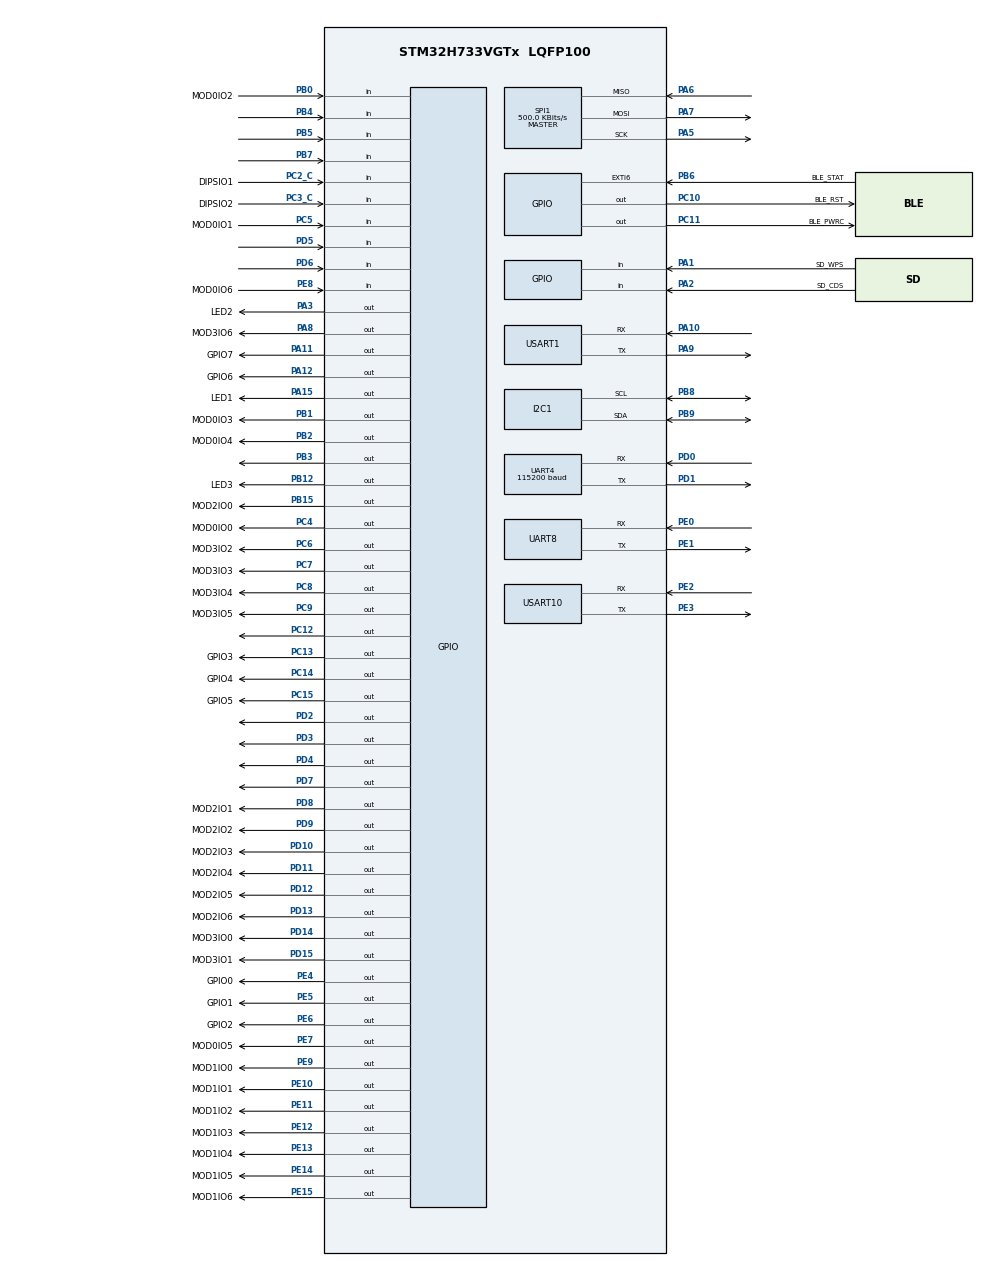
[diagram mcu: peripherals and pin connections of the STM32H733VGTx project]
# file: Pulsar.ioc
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Dma.Request0=UART4_RX
Dma.UART4_RX.0.Direction=DMA_PERIPH_TO_MEMORY
Dma.UART4_RX.0.EventEnable=DISABLE
Dma.UART4_RX.0.FIFOMode=DMA_FIFOMODE_DISABLE
Dma.UART4_RX.0.Instance=DMA1_Stream0
Dma.UART4_RX.0.MemDataAlignment=DMA_MDATAALIGN_BYTE
Dma.UART4_RX.0.MemInc=DMA_MINC_ENABLE
Dma.UART4_RX.0.Mode=DMA_NORMAL
Dma.UART4_RX.0.PeriphDataAlignment=DMA_PDATAALIGN_BYTE
Dma.UART4_RX.0.PeriphInc=DMA_PINC_DISABLE
Dma.UART4_RX.0.Polarity=HAL_DMAMUX_REQ_GEN_RISING
Dma.UART4_RX.0.Priority=DMA_PRIORITY_MEDIUM
Dma.UART4_RX.0.RequestNumber=1
Dma.UART4_RX.0.SignalID=NONE
Dma.UART4_RX.0.SyncEnable=DISABLE
Dma.UART4_RX.0.SyncPolarity=HAL_DMAMUX_SYNC_NO_EVENT
Dma.UART4_RX.0.SyncRequestNumber=1
Dma.UART4_RX.0.SyncSignalID=NONE
FREERTOS.Tasks01=defaultTask,8,128,StartDefaultTask,Default,NULL,Dynamic,NULL,NULL;LEDs,16,128,LEDsTask,As external,NULL,Dynamic,NULL,NULL;Bluetooth,24,128,BluetoothTask,As external,NULL,Dynamic,NULL,NULL;Radio,32,2048,RadioTask,As external,NULL,Dynamic,NULL,NULL
FREERTOS.configENABLE_FPU=1
I2C1.Timing=0x00909BEB
Mcu.Family=STM32H7
Mcu.Name=STM32H733VGTx
Mcu.Package=LQFP100
NVIC.DMA1_Stream0_IRQn=true\:5\:0\:false\:false\:true\:true\:false\:true\:true
NVIC.EXTI9_5_IRQn=true\:5\:0\:true\:false\:true\:true\:true\:true\:true
NVIC.PriorityGroup=NVIC_PRIORITYGROUP_4
NVIC.TIM1_UP_IRQn=true\:15\:0\:false\:false\:true\:false\:false\:true\:true
NVIC.TimeBase=TIM1_UP_IRQn
NVIC.TimeBaseIP=TIM1
NVIC.UART4_IRQn=true\:5\:0\:false\:false\:true\:true\:true\:true\:true
PA0.Signal=SDMMC2_CMD
PA1.GPIO_Label=SD_WPS
PA1.Signal=GPIO_Input
PA10.Mode=Asynchronous
PA10.Signal=USART1_RX
PA11.GPIO_Label=GPIO7
PA11.Signal=GPIO_Output
PA12.GPIO_Label=GPIO6
PA12.Signal=GPIO_Output
PA13(JTMS/SWDIO).Mode=Serial_Wire
PA13(JTMS/SWDIO).Signal=DEBUG_JTMS-SWDIO
PA14(JTCK/SWCLK).Mode=Serial_Wire
PA14(JTCK/SWCLK).Signal=DEBUG_JTCK-SWCLK
PA15(JTDI).GPIO_Label=LED1
PA15(JTDI).PinState=GPIO_PIN_SET
PA15(JTDI).Signal=GPIO_Output
PA2.GPIO_Label=SD_CDS
PA2.Signal=GPIO_Input
PA3.GPIO_Label=LED2
PA3.PinState=GPIO_PIN_SET
PA3.Signal=GPIO_Output
PA5.GPIO_Speed=GPIO_SPEED_FREQ_HIGH
PA5.Mode=Full_Duplex_Master
PA5.Signal=SPI1_SCK
PA6.GPIO_Speed=GPIO_SPEED_FREQ_HIGH
PA6.Mode=Full_Duplex_Master
PA6.Signal=SPI1_MISO
PA7.GPIO_Speed=GPIO_SPEED_FREQ_HIGH
PA7.Mode=Full_Duplex_Master
PA7.Signal=SPI1_MOSI
PA8.GPIO_Label=MOD3IO6
PA8.Signal=GPIO_Output
PA9.Mode=Asynchronous
PA9.Signal=USART1_TX
PB0.GPIO_Label=MOD0IO2
PB0.Signal=GPIO_Input
PB1.GPIO_Label=MOD0IO3
PB1.PinState=GPIO_PIN_SET
PB1.Signal=GPIO_Output
PB12.GPIO_Label=LED3
PB12.PinState=GPIO_PIN_RESET
PB12.Signal=GPIO_Output
PB14.Signal=SDMMC2_D0
PB15.GPIO_Label=MOD2IO0
PB15.Signal=GPIO_Output
PB2.GPIO_Label=MOD0IO4
PB2.Signal=GPIO_Output
PB3(JTDO/TRACESWO).Signal=GPIO_Output
PB4(NJTRST).Signal=GPIO_Input
PB5.Signal=GPIO_Input
PB6.GPIO_Label=BLE_STAT
PB6.GPIO_ModeDefaultEXTI=GPIO_MODE_IT_RISING_FALLING
PB6.Signal=GPXTI6
PB7.Signal=GPIO_Input
PB8.Mode=I2C
PB8.Signal=I2C1_SCL
PB9.Mode=I2C
PB9.Signal=I2C1_SDA
PC1.Signal=SDMMC2_CK
PC10.GPIO_Label=BLE_RST
PC10.PinState=GPIO_PIN_SET
PC10.Signal=GPIO_Output
PC11.GPIO_Label=BLE_PWRC
PC11.PinState=GPIO_PIN_SET
PC11.Signal=GPIO_Output
PC12.Signal=GPIO_Output
PC13.GPIO_Label=GPIO3
PC13.Signal=GPIO_Output
PC14-OSC32_IN.GPIO_Label=GPIO4
PC14-OSC32_IN.Signal=GPIO_Output
PC15-OSC32_OUT.GPIO_Label=GPIO5
PC15-OSC32_OUT.Signal=GPIO_Output
PC2_C.GPIO_Label=DIPSIO1
PC2_C.Signal=GPIO_Input
PC3_C.GPIO_Label=DIPSIO2
PC3_C.Signal=GPIO_Input
PC4.GPIO_Label=MOD0IO0
PC4.GPIO_Speed=GPIO_SPEED_FREQ_LOW
PC4.PinState=GPIO_PIN_SET
PC4.Signal=GPIO_Output
PC5.GPIO_Label=MOD0IO1
PC5.Signal=GPIO_Input
PC6.GPIO_Label=MOD3IO2
PC6.Signal=GPIO_Output
PC7.GPIO_Label=MOD3IO3
PC7.Signal=GPIO_Output
PC8.GPIO_Label=MOD3IO4
PC8.Signal=GPIO_Output
PC9.GPIO_Label=MOD3IO5
PC9.Signal=GPIO_Output
PD0.Mode=Asynchronous
PD0.Signal=UART4_RX
PD1.Mode=Asynchronous
PD1.Signal=UART4_TX
PD10.GPIO_Label=MOD2IO3
PD10.Signal=GPIO_Output
PD11.GPIO_Label=MOD2IO4
PD11.Signal=GPIO_Output
PD12.GPIO_Label=MOD2IO5
PD12.Signal=GPIO_Output
PD13.GPIO_Label=MOD2IO6
PD13.Signal=GPIO_Output
PD14.GPIO_Label=MOD3IO0
PD14.Signal=GPIO_Output
PD15.GPIO_Label=MOD3IO1
PD15.Signal=GPIO_Output
PD2.Signal=GPIO_Output
PD3.Signal=GPIO_Output
PD4.Signal=GPIO_Output
PD5.Signal=GPIO_Input
PD6.Signal=GPIO_Input
PD7.Signal=GPIO_Output
PD8.GPIO_Label=MOD2IO1
PD8.Signal=GPIO_Output
PD9.GPIO_Label=MOD2IO2
PD9.Signal=GPIO_Output
PE0.Mode=Asynchronous
PE0.Signal=UART8_RX
PE1.Mode=Asynchronous
PE1.Signal=UART8_TX
PE10.GPIO_Label=MOD1IO1
PE10.Signal=GPIO_Output
PE11.GPIO_Label=MOD1IO2
PE11.Signal=GPIO_Output
PE12.GPIO_Label=MOD1IO3
PE12.Signal=GPIO_Output
PE13.GPIO_Label=MOD1IO4
PE13.Signal=GPIO_Output
PE14.GPIO_Label=MOD1IO5
PE14.Signal=GPIO_Output
PE15.GPIO_Label=MOD1IO6
PE15.Signal=GPIO_Output
PE2.Mode=Asynchronous
PE2.Signal=USART10_RX
PE3.Mode=Asynchronous
PE3.Signal=USART10_TX
PE4.GPIO_Label=GPIO0
PE4.Signal=GPIO_Output
PE5.GPIO_Label=GPIO1
PE5.Signal=GPIO_Output
PE6.GPIO_Label=GPIO2
PE6.Signal=GPIO_Output
PE7.GPIO_Label=MOD0IO5
PE7.PinState=GPIO_PIN_RESET
PE7.Signal=GPIO_Output
PE8.GPIO_Label=MOD0IO6
PE8.Signal=GPIO_Input
PE9.GPIO_Label=MOD1IO0
PE9.Signal=GPIO_Output
PH0-OSC_IN.Mode=HSE-External-Oscillator
PH0-OSC_IN.Signal=RCC_OSC_IN
PH1-OSC_OUT.Mode=HSE-External-Oscillator
PH1-OSC_OUT.Signal=RCC_OSC_OUT
ProjectManager.HeapSize=0x200
ProjectManager.StackSize=0x400
ProjectManager.TargetToolchain=MDK-ARM V5.32
RCC.ADCFreq_Value=40000000
RCC.APB1Freq_Value=80000000
RCC.APB2Freq_Value=80000000
RCC.APB3Freq_Value=80000000
RCC.APB4Freq_Value=80000000
RCC.CortexFreq_Value=80000000
RCC.D1CPRE=RCC_SYSCLK_DIV2
RCC.DIVM1=2
RCC.DIVM2=2
RCC.DIVM3=2
RCC.DIVN1=80
RCC.DIVN2=80
RCC.DIVN3=80
RCC.DIVP2=8
RCC.DIVP3=8
RCC.DIVQ1=40
RCC.DIVQ2=80
RCC.DIVQ3=8
RCC.DIVR1=8
RCC.DIVR3=8
RCC.HCLKFreq_Value=80000000
RCC.HSE_VALUE=8000000
RCC.I2C123CLockSelection=RCC_I2C1235CLKSOURCE_PLL3
RCC.PLLSourceVirtual=RCC_PLLSOURCE_HSE
RCC.SYSCLKFreq_VALUE=160000000
RCC.SYSCLKSource=RCC_SYSCLKSOURCE_PLLCLK
RCC.USART16CLockSelection=RCC_USART16910CLKSOURCE_PLL2
RCC.USART234578CLockSelection=RCC_USART234578CLKSOURCE_PLL2
RCC.USBFreq_Value=8000000
SPI1.BaudRatePrescaler=SPI_BAUDRATEPRESCALER_16
SPI1.CRCCalculation=SPI_CRCCALCULATION_DISABLE
SPI1.CalculateBaudRate=500.0 KBits/s
SPI1.DataSize=SPI_DATASIZE_8BIT
SPI1.Direction=SPI_DIRECTION_2LINES
SPI1.Mode=SPI_MODE_MASTER
SPI1.VirtualType=VM_MASTER
UART4.AutoBaudRateEnableParam=UART_ADVFEATURE_AUTOBAUDRATE_DISABLE
UART4.BaudRate=115200
USART1.VirtualMode-Asynchronous=VM_ASYNC
USART10.VirtualMode=VM_ASYNC
VP_FREERTOS_VS_CMSIS_V2.Mode=CMSIS_V2
VP_MEMORYMAP_VS_MEMORYMAP.Mode=CurAppReg
VP_SYS_VS_tim1.Mode=TIM1
board=custom

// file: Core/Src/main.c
/* USER CODE BEGIN Header */
/**
  ******************************************************************************
  * @file           : main.c
  * @brief          : Main program body
  ******************************************************************************
  * @attention
  *
  * Copyright (c) 2026 STMicroelectronics.
  * All rights reserved.
  *
  * This software is licensed under terms that can be found in the LICENSE file
  * in the root directory of this software component.
  * If no LICENSE file comes with this software, it is provided AS-IS.
  *
  ******************************************************************************
  */
/* USER CODE END Header */
#include "main.h"
#include "cmsis_os.h"
#include "dma.h"
#include "i2c.h"
#include "spi.h"
#include "usart.h"
#include "gpio.h"

/* USER CODE BEGIN Includes */
#include "ui.h"
#include "bluetooth.h"
/* USER CODE END Includes */

void SystemClock_Config(void);
void PeriphCommonClock_Config(void);
void MX_FREERTOS_Init(void);

int main(void)
{

  /* MCU Configuration--------------------------------------------------------*/

  /* Reset of all peripherals, Initializes the Flash interface and the Systick. */
  HAL_Init();

  /* Configure the system clock */
  SystemClock_Config();

  /* Configure the peripherals common clocks */
  PeriphCommonClock_Config();

  /* Initialize all configured peripherals */
  MX_GPIO_Init();
  MX_DMA_Init();
  MX_I2C1_Init();
  MX_SPI1_Init();
  MX_USART1_UART_Init();
  MX_UART4_Init();
  MX_UART8_Init();
  MX_USART10_UART_Init();
  /* USER CODE BEGIN 2 */
  DIPsSettingsReading();
  /* USER CODE END 2 */

  /* Init scheduler */
  osKernelInitialize();

  /* Call init function for freertos objects (in cmsis_os2.c) */
  MX_FREERTOS_Init();

  /* Start scheduler */
  osKernelStart();

  /* We should never get here as control is now taken by the scheduler */

  /* Infinite loop */
  while (1)
  {

  }
}

void SystemClock_Config(void)
{
  RCC_OscInitTypeDef RCC_OscInitStruct = {0};
  RCC_ClkInitTypeDef RCC_ClkInitStruct = {0};

  /** Supply configuration update enable
  */
  HAL_PWREx_ConfigSupply(PWR_LDO_SUPPLY);

  /** Configure the main internal regulator output voltage
  */
  __HAL_PWR_VOLTAGESCALING_CONFIG(PWR_REGULATOR_VOLTAGE_SCALE3);

  while(!__HAL_PWR_GET_FLAG(PWR_FLAG_VOSRDY)) {}

  /** Initializes the RCC Oscillators according to the specified parameters
  * in the RCC_OscInitTypeDef structure.
  */
  RCC_OscInitStruct.OscillatorType = RCC_OSCILLATORTYPE_HSE;
  RCC_OscInitStruct.HSEState = RCC_HSE_ON;
  RCC_OscInitStruct.PLL.PLLState = RCC_PLL_ON;
  RCC_OscInitStruct.PLL.PLLSource = RCC_PLLSOURCE_HSE;
  RCC_OscInitStruct.PLL.PLLM = 2;
  RCC_OscInitStruct.PLL.PLLN = 80;
  RCC_OscInitStruct.PLL.PLLP = 2;
  RCC_OscInitStruct.PLL.PLLQ = 40;
  RCC_OscInitStruct.PLL.PLLR = 8;
  RCC_OscInitStruct.PLL.PLLRGE = RCC_PLL1VCIRANGE_2;
  RCC_OscInitStruct.PLL.PLLVCOSEL = RCC_PLL1VCOWIDE;
  RCC_OscInitStruct.PLL.PLLFRACN = 0;
  if (HAL_RCC_OscConfig(&RCC_OscInitStruct) != HAL_OK)
  {
    Error_Handler();
  }

  /** Initializes the CPU, AHB and APB buses clocks
  */
  RCC_ClkInitStruct.ClockType = RCC_CLOCKTYPE_HCLK|RCC_CLOCKTYPE_SYSCLK
                              |RCC_CLOCKTYPE_PCLK1|RCC_CLOCKTYPE_PCLK2
                              |RCC_CLOCKTYPE_D3PCLK1|RCC_CLOCKTYPE_D1PCLK1;
  RCC_ClkInitStruct.SYSCLKSource = RCC_SYSCLKSOURCE_PLLCLK;
  RCC_ClkInitStruct.SYSCLKDivider = RCC_SYSCLK_DIV2;
  RCC_ClkInitStruct.AHBCLKDivider = RCC_HCLK_DIV1;
  RCC_ClkInitStruct.APB3CLKDivider = RCC_APB3_DIV1;
  RCC_ClkInitStruct.APB1CLKDivider = RCC_APB1_DIV1;
  RCC_ClkInitStruct.APB2CLKDivider = RCC_APB2_DIV1;
  RCC_ClkInitStruct.APB4CLKDivider = RCC_APB4_DIV1;

  if (HAL_RCC_ClockConfig(&RCC_ClkInitStruct, FLASH_LATENCY_2) != HAL_OK)
  {
    Error_Handler();
  }
}

void PeriphCommonClock_Config(void)
{
  RCC_PeriphCLKInitTypeDef PeriphClkInitStruct = {0};

  /** Initializes the peripherals clock
  */
  PeriphClkInitStruct.PeriphClockSelection = RCC_PERIPHCLK_UART8|RCC_PERIPHCLK_USART1
                              |RCC_PERIPHCLK_USART10|RCC_PERIPHCLK_UART4;
  PeriphClkInitStruct.PLL2.PLL2M = 2;
  PeriphClkInitStruct.PLL2.PLL2N = 80;
  PeriphClkInitStruct.PLL2.PLL2P = 8;
  PeriphClkInitStruct.PLL2.PLL2Q = 80;
  PeriphClkInitStruct.PLL2.PLL2R = 2;
  PeriphClkInitStruct.PLL2.PLL2RGE = RCC_PLL2VCIRANGE_2;
  PeriphClkInitStruct.PLL2.PLL2VCOSEL = RCC_PLL2VCOWIDE;
  PeriphClkInitStruct.PLL2.PLL2FRACN = 0;
  PeriphClkInitStruct.Usart234578ClockSelection = RCC_USART234578CLKSOURCE_PLL2;
  PeriphClkInitStruct.Usart16ClockSelection = RCC_USART16910CLKSOURCE_PLL2;
  if (HAL_RCCEx_PeriphCLKConfig(&PeriphClkInitStruct) != HAL_OK)
  {
    Error_Handler();
  }
}

/* USER CODE BEGIN 4 */
void HAL_UART_RxCpltCallback(UART_HandleTypeDef *huart)
{
    if (huart->Instance == UART4)
    {
        BluetoothUARTCallback(huart);
    }
}

void HAL_GPIO_EXTI_Callback(uint16_t GPIO_Pin)
{
    if (GPIO_Pin == BLE_STAT_Pin)
    {
        BluetoothStatChange();
    }
}
/* USER CODE END 4 */

void HAL_TIM_PeriodElapsedCallback(TIM_HandleTypeDef *htim)
{
  if (htim->Instance == TIM1)
  {
    HAL_IncTick();
  }
}

void Error_Handler(void)
{
  __disable_irq();
  while (1)
  {
  }
}

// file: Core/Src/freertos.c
/* USER CODE BEGIN Header */
/**
  ******************************************************************************
  * File Name          : freertos.c
  * Description        : Code for freertos applications
  ******************************************************************************
  * @attention
  *
  * Copyright (c) 2026 STMicroelectronics.
  * All rights reserved.
  *
  * This software is licensed under terms that can be found in the LICENSE file
  * in the root directory of this software component.
  * If no LICENSE file comes with this software, it is provided AS-IS.
  *
  ******************************************************************************
  */
/* USER CODE END Header */

#include "FreeRTOS.h"
#include "task.h"
#include "main.h"
#include "cmsis_os.h"

/* Definitions for defaultTask */
osThreadId_t defaultTaskHandle;
const osThreadAttr_t defaultTask_attributes = {
  .name = "defaultTask",
  .stack_size = 128 * 4,
  .priority = (osPriority_t) osPriorityLow,
};
/* Definitions for LEDs */
osThreadId_t LEDsHandle;
const osThreadAttr_t LEDs_attributes = {
  .name = "LEDs",
  .stack_size = 128 * 4,
  .priority = (osPriority_t) osPriorityBelowNormal,
};
/* Definitions for Bluetooth */
osThreadId_t BluetoothHandle;
const osThreadAttr_t Bluetooth_attributes = {
  .name = "Bluetooth",
  .stack_size = 128 * 4,
  .priority = (osPriority_t) osPriorityNormal,
};
/* Definitions for Radio */
osThreadId_t RadioHandle;
const osThreadAttr_t Radio_attributes = {
  .name = "Radio",
  .stack_size = 2048 * 4,
  .priority = (osPriority_t) osPriorityAboveNormal,
};

void StartDefaultTask(void *argument);
extern void LEDsTask(void *argument);
extern void BluetoothTask(void *argument);
extern void RadioTask(void *argument);

void MX_FREERTOS_Init(void); /* (MISRA C 2004 rule 8.1) */

void MX_FREERTOS_Init(void) {

  /* Create the thread(s) */
  /* creation of defaultTask */
  defaultTaskHandle = osThreadNew(StartDefaultTask, NULL, &defaultTask_attributes);

  /* creation of LEDs */
  LEDsHandle = osThreadNew(LEDsTask, NULL, &LEDs_attributes);

  /* creation of Bluetooth */
  BluetoothHandle = osThreadNew(BluetoothTask, NULL, &Bluetooth_attributes);

  /* creation of Radio */
  RadioHandle = osThreadNew(RadioTask, NULL, &Radio_attributes);

}

void StartDefaultTask(void *argument)
{
  /* USER CODE BEGIN StartDefaultTask */
  HAL_GPIO_WritePin(LED1_GPIO_Port, LED1_Pin, RESET);   // Turns off the red led to signal the kernel has started
  /* Infinite loop */
  for(;;)
  {
    osDelay(1);
  }
  /* USER CODE END StartDefaultTask */
}
